VERSION ""

NS_ :

BS_:

BU_: VCU BMS ECUMASTER_GPS_IMU AMK_RL

BO_ 256 VCU_STATUS: 4 Vector__XXX
 SG_ VEHICLE_STATE : 0|2@1+ (1,0) [0|3] "Enum" Vector__XXX
 SG_ TORQUE_PLAUSIBLE : 2|1@1+ (1,0) [0|1] "Bool" Vector__XXX
 SG_ PEDALS_PLAUSIBLE : 3|1@1+ (1,0) [0|1] "Bool" Vector__XXX
 SG_ TORQUE_DERATING : 4|1@1+ (1,0) [0|0] "Bool" Vector__XXX
 SG_ VCU_EEPROM_STATE : 5|2@1+ (1,0) [0|0] "Enum" Vector__XXX
 SG_ CAN_PLAUSIBLE : 7|1@1+ (1,0) [0|1] "Bool" Vector__XXX
 SG_ APPS_1_PLAUSIBLE : 8|1@1+ (1,0) [0|1] "Bool" Vector__XXX
 SG_ APPS_1_CONFIG_PLAUSIBLE : 9|1@1+ (1,0) [0|1] "Bool" Vector__XXX
 SG_ APPS_2_PLAUSIBLE : 10|1@1+ (1,0) [0|1] "Bool" Vector__XXX
 SG_ APPS_2_CONFIG_PLAUSIBLE : 11|1@1+ (1,0) [0|1] "Bool" Vector__XXX
 SG_ BSE_F_PLAUSIBLE : 12|1@1+ (1,0) [0|1] "Bool" Vector__XXX
 SG_ BSE_F_CONFIG_PLAUSIBLE : 13|1@1+ (1,0) [0|1] "Bool" Vector__XXX
 SG_ BSE_R_PLAUSIBLE : 14|1@1+ (1,0) [0|1] "Bool" Vector__XXX
 SG_ BSE_R_CONFIG_PLAUSIBLE : 15|1@1+ (1,0) [0|1] "Bool" Vector__XXX
 SG_ AMK_RL_VALID : 16|1@1+ (1,0) [0|0] "Bool" Vector__XXX
 SG_ AMK_RR_VALID : 17|1@1+ (1,0) [0|0] "Bool" Vector__XXX
 SG_ AMK_FL_VALID : 18|1@1+ (1,0) [0|0] "Bool" Vector__XXX
 SG_ AMK_FR_VALID : 19|1@1+ (1,0) [0|0] "Bool" Vector__XXX
 SG_ GPS_VALID : 20|1@1+ (1,0) [0|0] "Bool" Vector__XXX
 SG_ GLV_BATTERY_VOLTAGE : 24|8@1+ (0.070588235294,0) [0|18] "V" Vector__XXX

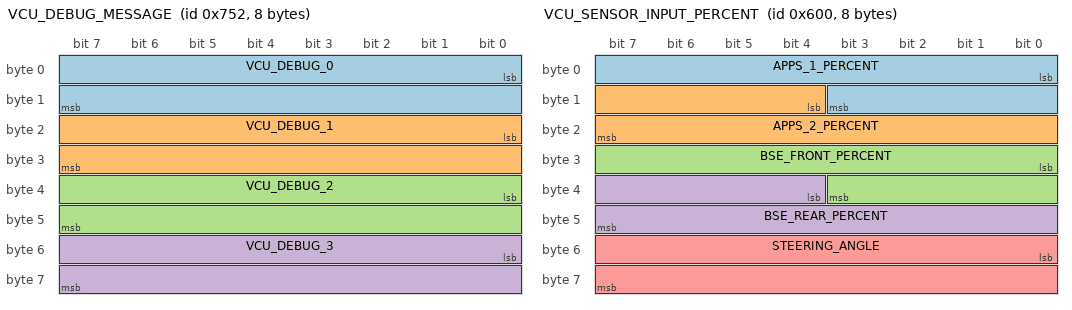
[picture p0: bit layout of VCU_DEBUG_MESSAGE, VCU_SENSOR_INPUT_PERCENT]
BO_ 1874 VCU_DEBUG_MESSAGE: 8 Vector__XXX
 SG_ VCU_DEBUG_0 : 0|16@1- (0.01,0) [0|0] "" Vector__XXX
 SG_ VCU_DEBUG_1 : 16|16@1- (0.01,0) [0|0] "" Vector__XXX
 SG_ VCU_DEBUG_2 : 32|16@1- (0.01,0) [0|0] "" Vector__XXX
 SG_ VCU_DEBUG_3 : 48|16@1- (0.01,0) [0|0] "" Vector__XXX

BO_ 1536 VCU_SENSOR_INPUT_PERCENT: 8 VCU
 SG_ APPS_1_PERCENT : 0|12@1+ (0.02442002442002442,0) [0|100] "%" Vector__XXX
 SG_ APPS_2_PERCENT : 12|12@1+ (0.02442002442002442,0) [0|100] "%" Vector__XXX
 SG_ BSE_FRONT_PERCENT : 24|12@1+ (0.02442002442002442,0) [0|100] "%" Vector__XXX
 SG_ BSE_REAR_PERCENT : 36|12@1+ (0.02442002442002442,0) [0|100] "%" Vector__XXX
 SG_ STEERING_ANGLE : 48|16@1- (0.005493247882810711,0) [-180|180] "Deg" Vector__XXX

BO_ 1284 AMK_RL_ERRORS_1: 8 AMK_RL
 SG_ RL_DIAGNOSTIC_NUMBER : 0|32@1+ (1,0) [0|0] "Word" Vector__XXX
 SG_ RL_ERROR_INFO_1 : 32|32@1+ (1,0) [0|0] "Word" Vector__XXX

BO_ 1288 AMK_RL_ERRORS_2: 8 AMK_RL
 SG_ RL_ERROR_INFO_2 : 0|32@1+ (1,0) [0|0] "Word" Vector__XXX
 SG_ RL_ERROR_INFO_3 : 32|32@1+ (1,0) [0|0] "Word" Vector__XXX

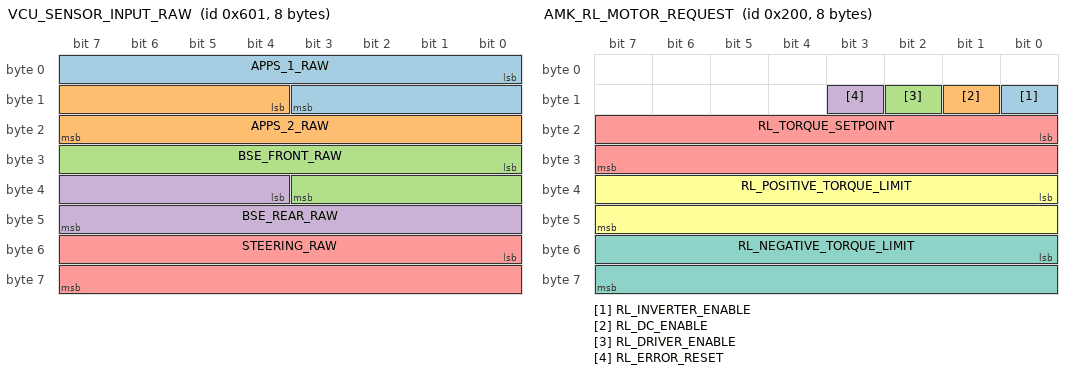
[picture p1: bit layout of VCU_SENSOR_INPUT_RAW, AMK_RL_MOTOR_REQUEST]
BO_ 1537 VCU_SENSOR_INPUT_RAW: 8 VCU
 SG_ APPS_1_RAW : 0|12@1+ (1,0) [0|4095] "Counts" Vector__XXX
 SG_ APPS_2_RAW : 12|12@1+ (1,0) [0|4095] "Counts" Vector__XXX
 SG_ BSE_FRONT_RAW : 24|12@1+ (1,0) [0|4095] "Counts" Vector__XXX
 SG_ BSE_REAR_RAW : 36|12@1+ (1,0) [0|4095] "Counts" Vector__XXX
 SG_ STEERING_RAW : 48|16@1+ (1,0) [0|4095] "Counts" Vector__XXX

BO_ 512 AMK_RL_MOTOR_REQUEST: 8 AMK_RL
 SG_ RL_INVERTER_ENABLE : 8|1@1+ (0,0) [0|0] "" Vector__XXX
 SG_ RL_DC_ENABLE : 9|1@1+ (0,0) [0|0] "" Vector__XXX
 SG_ RL_DRIVER_ENABLE : 10|1@1+ (0,0) [0|0] "" Vector__XXX
 SG_ RL_ERROR_RESET : 11|1@1+ (0,0) [0|0] "" Vector__XXX
 SG_ RL_TORQUE_SETPOINT : 16|16@1- (0.0098,0) [-21|21] "Nm" Vector__XXX
 SG_ RL_POSITIVE_TORQUE_LIMIT : 32|16@1- (0.0098,0) [0|21] "Nm" Vector__XXX
 SG_ RL_NEGATIVE_TORQUE_LIMIT : 48|16@1- (0.0098,0) [0|21] "Nm" Vector__XXX

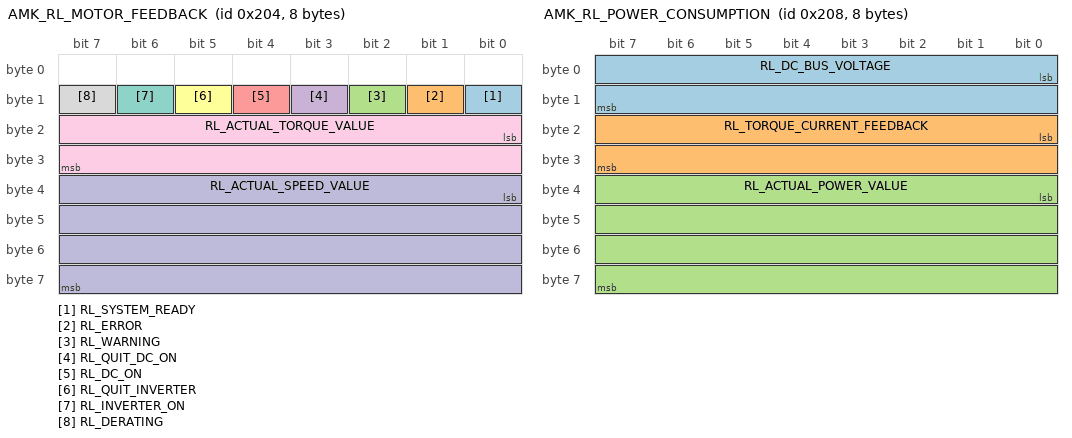
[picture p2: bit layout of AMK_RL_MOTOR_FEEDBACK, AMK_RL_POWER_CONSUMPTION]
BO_ 516 AMK_RL_MOTOR_FEEDBACK: 8 AMK_RL
 SG_ RL_SYSTEM_READY : 8|1@1+ (1,0) [0|0] "Bool" Vector__XXX
 SG_ RL_ERROR : 9|1@1+ (1,0) [0|0] "Bool" Vector__XXX
 SG_ RL_WARNING : 10|1@1+ (1,0) [0|0] "Bool" Vector__XXX
 SG_ RL_QUIT_DC_ON : 11|1@1+ (1,0) [0|0] "Bool" Vector__XXX
 SG_ RL_DC_ON : 12|1@1+ (1,0) [0|0] "Bool" Vector__XXX
 SG_ RL_QUIT_INVERTER : 13|1@1+ (1,0) [0|0] "Bool" Vector__XXX
 SG_ RL_INVERTER_ON : 14|1@1+ (1,0) [0|0] "Bool" Vector__XXX
 SG_ RL_DERATING : 15|1@1+ (1,0) [0|0] "Bool" Vector__XXX
 SG_ RL_ACTUAL_TORQUE_VALUE : 16|16@1- (0.0098,0) [0|0] "Nm" Vector__XXX
 SG_ RL_ACTUAL_SPEED_VALUE : 32|32@1- (0.00001,0) [0|0] "RPM" Vector__XXX

BO_ 520 AMK_RL_POWER_CONSUMPTION: 8 AMK_RL
 SG_ RL_DC_BUS_VOLTAGE : 0|16@1+ (1,0) [0|0] "V" Vector__XXX
 SG_ RL_TORQUE_CURRENT_FEEDBACK : 16|16@1- (1,0) [0|0] "A" Vector__XXX
 SG_ RL_ACTUAL_POWER_VALUE : 32|32@1+ (1,0) [0|0] "W" Vector__XXX

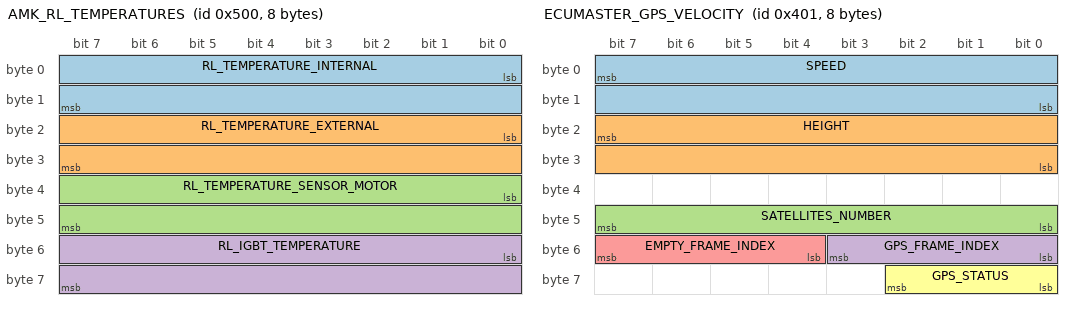
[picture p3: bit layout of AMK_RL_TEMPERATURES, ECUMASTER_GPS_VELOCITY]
BO_ 1280 AMK_RL_TEMPERATURES: 8 AMK_RL
 SG_ RL_TEMPERATURE_INTERNAL : 0|16@1- (0.1,0) [0|0] "C" Vector__XXX
 SG_ RL_TEMPERATURE_EXTERNAL : 16|16@1- (0.1,0) [0|0] "C" Vector__XXX
 SG_ RL_TEMPERATURE_SENSOR_MOTOR : 32|16@1+ (0.1,0) [0|0] "C" Vector__XXX
 SG_ RL_IGBT_TEMPERATURE : 48|16@1- (0.1,0) [0|0] "C" Vector__XXX

BO_ 1024 ECUMASTER_GPS_POSITION: 8 ECUMASTER_GPS_IMU
 SG_ LATITUDE : 7|32@0- (1e-7,0) [-90|90] "deg" Vector__XXX
 SG_ LONGITUDE : 39|32@0- (1e-7,0) [-180|180] "deg" Vector__XXX

BO_ 1025 ECUMASTER_GPS_VELOCITY: 8 ECUMASTER_GPS_IMU
 SG_ SPEED : 7|16@0- (0.036,0) [-1179|1179] "km/h" Vector__XXX
 SG_ HEIGHT : 23|16@0- (1,0) [-32768|32767] "m" Vector__XXX
 SG_ SATELLITES_NUMBER : 47|8@0+ (1,0) [0|72] "" Vector__XXX
 SG_ GPS_FRAME_INDEX : 51|4@0+ (1,0) [0|16] "" Vector__XXX
 SG_ EMPTY_FRAME_INDEX : 55|4@0+ (1,0) [0|16] "" Vector__XXX
 SG_ GPS_STATUS : 58|3@0+ (1,0) [1|5] "" Vector__XXX

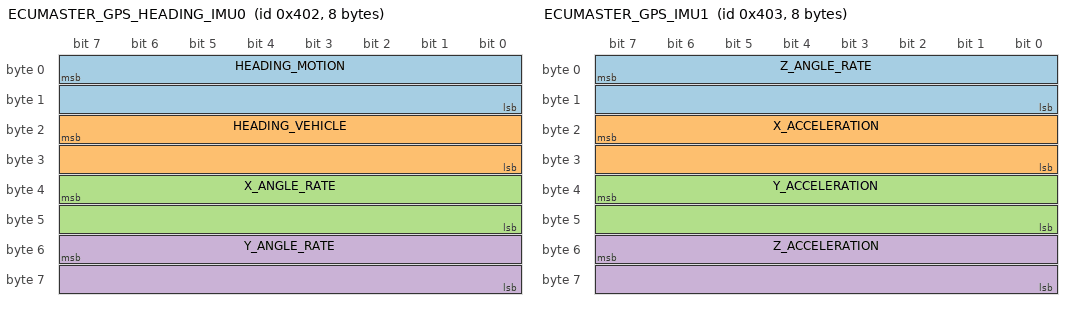
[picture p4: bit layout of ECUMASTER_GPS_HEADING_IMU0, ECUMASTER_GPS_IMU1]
BO_ 1026 ECUMASTER_GPS_HEADING_IMU0: 8 ECUMASTER_GPS_IMU
 SG_ HEADING_MOTION : 7|16@0+ (1,0) [0|360] "deg" Vector__XXX
 SG_ HEADING_VEHICLE : 23|16@0+ (1,0) [0|360] "deg" Vector__XXX
 SG_ X_ANGLE_RATE : 39|16@0- (0.01,0) [-250|250] "deg/s" Vector__XXX
 SG_ Y_ANGLE_RATE : 55|16@0- (0.01,0) [-250|250] "deg/s" Vector__XXX

BO_ 1027 ECUMASTER_GPS_IMU1: 8 ECUMASTER_GPS_IMU
 SG_ Z_ANGLE_RATE : 7|16@0- (0.01,0) [-250|250] "deg/s" Vector__XXX
 SG_ X_ACCELERATION : 23|16@0- (0.01,0) [-4|4] "g" Vector__XXX
 SG_ Y_ACCELERATION : 39|16@0- (0.01,0) [-4|4] "g" Vector__XXX
 SG_ Z_ACCELERATION : 55|16@0- (0.01,0) [-4|4] "g" Vector__XXX

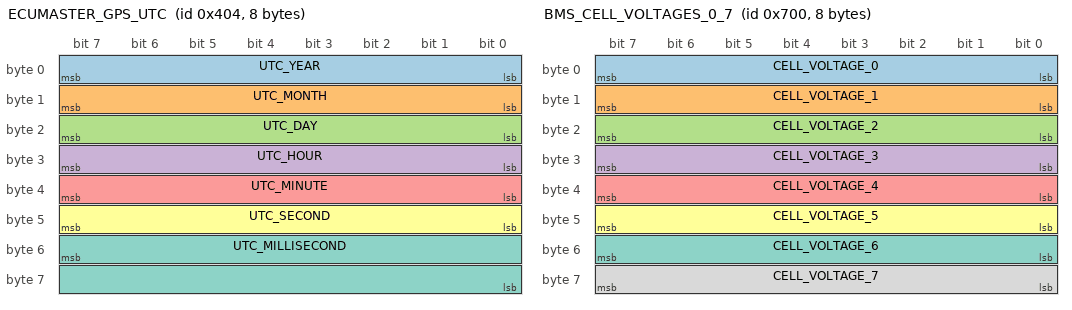
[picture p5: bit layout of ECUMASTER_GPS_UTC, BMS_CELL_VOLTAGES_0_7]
BO_ 1028 ECUMASTER_GPS_UTC: 8 ECUMASTER_GPS_IMU
 SG_ UTC_YEAR : 7|8@0+ (1,2000) [2000|2255] "years" Vector__XXX
 SG_ UTC_MONTH : 15|8@0+ (1,0) [1|12] "months" Vector__XXX
 SG_ UTC_DAY : 23|8@0+ (1,0) [1|31] "days" Vector__XXX
 SG_ UTC_HOUR : 31|8@0+ (1,0) [0|23] "hours" Vector__XXX
 SG_ UTC_MINUTE : 39|8@0+ (1,0) [0|59] "minutes" Vector__XXX
 SG_ UTC_SECOND : 47|8@0+ (1,0) [0|59] "s" Vector__XXX
 SG_ UTC_MILLISECOND : 55|16@0+ (0.0152587890625,0) [0|999.99] "ms" Vector__XXX

BO_ 1792 BMS_CELL_VOLTAGES_0_7: 8 BMS
 SG_ CELL_VOLTAGE_0 : 0|8@1+ (0.03125,0) [0|7.96875] "V" Vector__XXX
 SG_ CELL_VOLTAGE_1 : 8|8@1+ (0.03125,0) [0|7.96875] "V" Vector__XXX
 SG_ CELL_VOLTAGE_2 : 16|8@1+ (0.03125,0) [0|7.96875] "V" Vector__XXX
 SG_ CELL_VOLTAGE_3 : 24|8@1+ (0.03125,0) [0|7.96875] "V" Vector__XXX
 SG_ CELL_VOLTAGE_4 : 32|8@1+ (0.03125,0) [0|7.96875] "V" Vector__XXX
 SG_ CELL_VOLTAGE_5 : 40|8@1+ (0.03125,0) [0|7.96875] "V" Vector__XXX
 SG_ CELL_VOLTAGE_6 : 48|8@1+ (0.03125,0) [0|7.96875] "V" Vector__XXX
 SG_ CELL_VOLTAGE_7 : 56|8@1+ (0.03125,0) [0|7.96875] "V" Vector__XXX

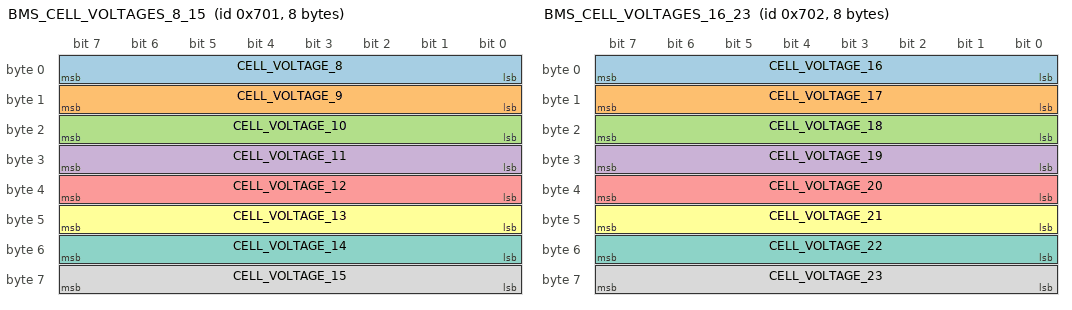
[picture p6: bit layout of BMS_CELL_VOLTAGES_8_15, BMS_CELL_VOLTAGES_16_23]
BO_ 1793 BMS_CELL_VOLTAGES_8_15: 8 BMS
 SG_ CELL_VOLTAGE_8 : 0|8@1+ (0.03125,0) [0|7.96875] "V" Vector__XXX
 SG_ CELL_VOLTAGE_9 : 8|8@1+ (0.03125,0) [0|7.96875] "V" Vector__XXX
 SG_ CELL_VOLTAGE_10 : 16|8@1+ (0.03125,0) [0|7.96875] "V" Vector__XXX
 SG_ CELL_VOLTAGE_11 : 24|8@1+ (0.03125,0) [0|7.96875] "V" Vector__XXX
 SG_ CELL_VOLTAGE_12 : 32|8@1+ (0.03125,0) [0|7.96875] "V" Vector__XXX
 SG_ CELL_VOLTAGE_13 : 40|8@1+ (0.03125,0) [0|7.96875] "V" Vector__XXX
 SG_ CELL_VOLTAGE_14 : 48|8@1+ (0.03125,0) [0|7.96875] "V" Vector__XXX
 SG_ CELL_VOLTAGE_15 : 56|8@1+ (0.03125,0) [0|7.96875] "V" Vector__XXX

BO_ 1794 BMS_CELL_VOLTAGES_16_23: 8 BMS
 SG_ CELL_VOLTAGE_16 : 0|8@1+ (0.03125,0) [0|7.96875] "V" Vector__XXX
 SG_ CELL_VOLTAGE_17 : 8|8@1+ (0.03125,0) [0|7.96875] "V" Vector__XXX
 SG_ CELL_VOLTAGE_18 : 16|8@1+ (0.03125,0) [0|7.96875] "V" Vector__XXX
 SG_ CELL_VOLTAGE_19 : 24|8@1+ (0.03125,0) [0|7.96875] "V" Vector__XXX
 SG_ CELL_VOLTAGE_20 : 32|8@1+ (0.03125,0) [0|7.96875] "V" Vector__XXX
 SG_ CELL_VOLTAGE_21 : 40|8@1+ (0.03125,0) [0|7.96875] "V" Vector__XXX
 SG_ CELL_VOLTAGE_22 : 48|8@1+ (0.03125,0) [0|7.96875] "V" Vector__XXX
 SG_ CELL_VOLTAGE_23 : 56|8@1+ (0.03125,0) [0|7.96875] "V" Vector__XXX

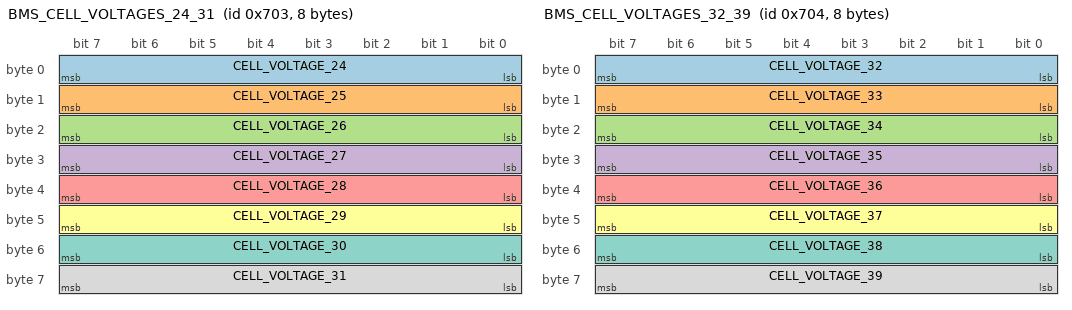
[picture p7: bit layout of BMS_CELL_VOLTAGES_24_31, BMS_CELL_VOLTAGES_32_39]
BO_ 1795 BMS_CELL_VOLTAGES_24_31: 8 BMS
 SG_ CELL_VOLTAGE_24 : 0|8@1+ (0.03125,0) [0|7.96875] "V" Vector__XXX
 SG_ CELL_VOLTAGE_25 : 8|8@1+ (0.03125,0) [0|7.96875] "V" Vector__XXX
 SG_ CELL_VOLTAGE_26 : 16|8@1+ (0.03125,0) [0|7.96875] "V" Vector__XXX
 SG_ CELL_VOLTAGE_27 : 24|8@1+ (0.03125,0) [0|7.96875] "V" Vector__XXX
 SG_ CELL_VOLTAGE_28 : 32|8@1+ (0.03125,0) [0|7.96875] "V" Vector__XXX
 SG_ CELL_VOLTAGE_29 : 40|8@1+ (0.03125,0) [0|7.96875] "V" Vector__XXX
 SG_ CELL_VOLTAGE_30 : 48|8@1+ (0.03125,0) [0|7.96875] "V" Vector__XXX
 SG_ CELL_VOLTAGE_31 : 56|8@1+ (0.03125,0) [0|7.96875] "V" Vector__XXX

BO_ 1796 BMS_CELL_VOLTAGES_32_39: 8 BMS
 SG_ CELL_VOLTAGE_32 : 0|8@1+ (0.03125,0) [0|7.96875] "V" Vector__XXX
 SG_ CELL_VOLTAGE_33 : 8|8@1+ (0.03125,0) [0|7.96875] "V" Vector__XXX
 SG_ CELL_VOLTAGE_34 : 16|8@1+ (0.03125,0) [0|7.96875] "V" Vector__XXX
 SG_ CELL_VOLTAGE_35 : 24|8@1+ (0.03125,0) [0|7.96875] "V" Vector__XXX
 SG_ CELL_VOLTAGE_36 : 32|8@1+ (0.03125,0) [0|7.96875] "V" Vector__XXX
 SG_ CELL_VOLTAGE_37 : 40|8@1+ (0.03125,0) [0|7.96875] "V" Vector__XXX
 SG_ CELL_VOLTAGE_38 : 48|8@1+ (0.03125,0) [0|7.96875] "V" Vector__XXX
 SG_ CELL_VOLTAGE_39 : 56|8@1+ (0.03125,0) [0|7.96875] "V" Vector__XXX

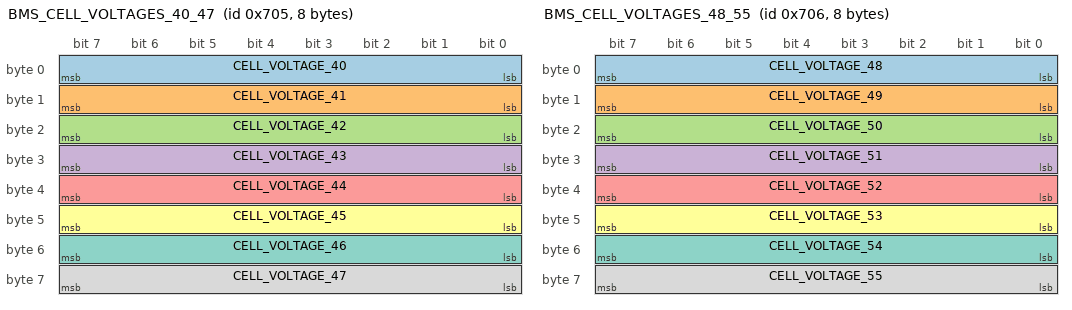
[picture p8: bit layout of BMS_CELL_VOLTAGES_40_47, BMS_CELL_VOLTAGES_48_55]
BO_ 1797 BMS_CELL_VOLTAGES_40_47: 8 BMS
 SG_ CELL_VOLTAGE_40 : 0|8@1+ (0.03125,0) [0|7.96875] "V" Vector__XXX
 SG_ CELL_VOLTAGE_41 : 8|8@1+ (0.03125,0) [0|7.96875] "V" Vector__XXX
 SG_ CELL_VOLTAGE_42 : 16|8@1+ (0.03125,0) [0|7.96875] "V" Vector__XXX
 SG_ CELL_VOLTAGE_43 : 24|8@1+ (0.03125,0) [0|7.96875] "V" Vector__XXX
 SG_ CELL_VOLTAGE_44 : 32|8@1+ (0.03125,0) [0|7.96875] "V" Vector__XXX
 SG_ CELL_VOLTAGE_45 : 40|8@1+ (0.03125,0) [0|7.96875] "V" Vector__XXX
 SG_ CELL_VOLTAGE_46 : 48|8@1+ (0.03125,0) [0|7.96875] "V" Vector__XXX
 SG_ CELL_VOLTAGE_47 : 56|8@1+ (0.03125,0) [0|7.96875] "V" Vector__XXX

BO_ 1798 BMS_CELL_VOLTAGES_48_55: 8 BMS
 SG_ CELL_VOLTAGE_48 : 0|8@1+ (0.03125,0) [0|7.96875] "V" Vector__XXX
 SG_ CELL_VOLTAGE_49 : 8|8@1+ (0.03125,0) [0|7.96875] "V" Vector__XXX
 SG_ CELL_VOLTAGE_50 : 16|8@1+ (0.03125,0) [0|7.96875] "V" Vector__XXX
 SG_ CELL_VOLTAGE_51 : 24|8@1+ (0.03125,0) [0|7.96875] "V" Vector__XXX
 SG_ CELL_VOLTAGE_52 : 32|8@1+ (0.03125,0) [0|7.96875] "V" Vector__XXX
 SG_ CELL_VOLTAGE_53 : 40|8@1+ (0.03125,0) [0|7.96875] "V" Vector__XXX
 SG_ CELL_VOLTAGE_54 : 48|8@1+ (0.03125,0) [0|7.96875] "V" Vector__XXX
 SG_ CELL_VOLTAGE_55 : 56|8@1+ (0.03125,0) [0|7.96875] "V" Vector__XXX

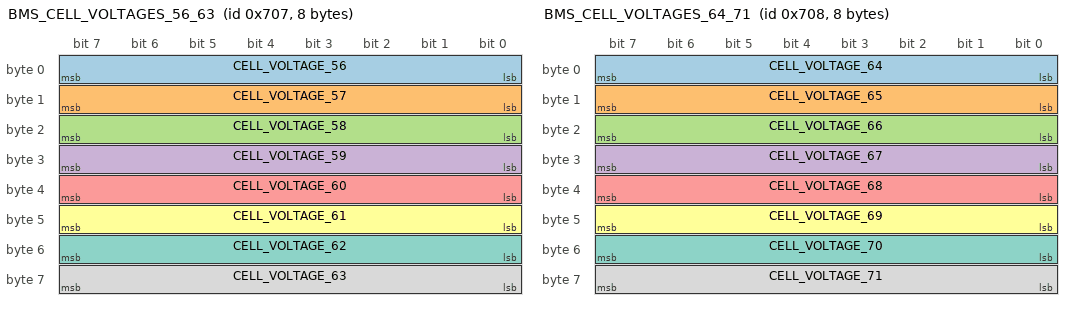
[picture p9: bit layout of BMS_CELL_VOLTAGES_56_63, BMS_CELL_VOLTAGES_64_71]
BO_ 1799 BMS_CELL_VOLTAGES_56_63: 8 BMS
 SG_ CELL_VOLTAGE_56 : 0|8@1+ (0.03125,0) [0|7.96875] "V" Vector__XXX
 SG_ CELL_VOLTAGE_57 : 8|8@1+ (0.03125,0) [0|7.96875] "V" Vector__XXX
 SG_ CELL_VOLTAGE_58 : 16|8@1+ (0.03125,0) [0|7.96875] "V" Vector__XXX
 SG_ CELL_VOLTAGE_59 : 24|8@1+ (0.03125,0) [0|7.96875] "V" Vector__XXX
 SG_ CELL_VOLTAGE_60 : 32|8@1+ (0.03125,0) [0|7.96875] "V" Vector__XXX
 SG_ CELL_VOLTAGE_61 : 40|8@1+ (0.03125,0) [0|7.96875] "V" Vector__XXX
 SG_ CELL_VOLTAGE_62 : 48|8@1+ (0.03125,0) [0|7.96875] "V" Vector__XXX
 SG_ CELL_VOLTAGE_63 : 56|8@1+ (0.03125,0) [0|7.96875] "V" Vector__XXX

BO_ 1800 BMS_CELL_VOLTAGES_64_71: 8 BMS
 SG_ CELL_VOLTAGE_64 : 0|8@1+ (0.03125,0) [0|7.96875] "V" Vector__XXX
 SG_ CELL_VOLTAGE_65 : 8|8@1+ (0.03125,0) [0|7.96875] "V" Vector__XXX
 SG_ CELL_VOLTAGE_66 : 16|8@1+ (0.03125,0) [0|7.96875] "V" Vector__XXX
 SG_ CELL_VOLTAGE_67 : 24|8@1+ (0.03125,0) [0|7.96875] "V" Vector__XXX
 SG_ CELL_VOLTAGE_68 : 32|8@1+ (0.03125,0) [0|7.96875] "V" Vector__XXX
 SG_ CELL_VOLTAGE_69 : 40|8@1+ (0.03125,0) [0|7.96875] "V" Vector__XXX
 SG_ CELL_VOLTAGE_70 : 48|8@1+ (0.03125,0) [0|7.96875] "V" Vector__XXX
 SG_ CELL_VOLTAGE_71 : 56|8@1+ (0.03125,0) [0|7.96875] "V" Vector__XXX

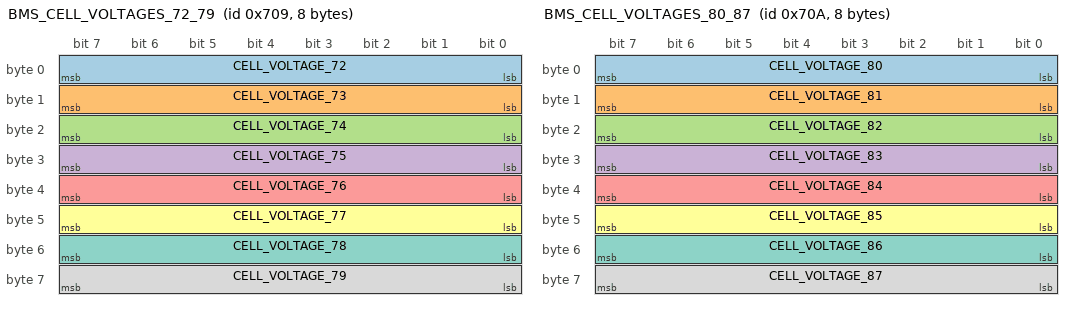
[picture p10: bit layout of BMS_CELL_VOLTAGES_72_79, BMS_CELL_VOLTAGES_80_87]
BO_ 1801 BMS_CELL_VOLTAGES_72_79: 8 BMS
 SG_ CELL_VOLTAGE_72 : 0|8@1+ (0.03125,0) [0|7.96875] "V" Vector__XXX
 SG_ CELL_VOLTAGE_73 : 8|8@1+ (0.03125,0) [0|7.96875] "V" Vector__XXX
 SG_ CELL_VOLTAGE_74 : 16|8@1+ (0.03125,0) [0|7.96875] "V" Vector__XXX
 SG_ CELL_VOLTAGE_75 : 24|8@1+ (0.03125,0) [0|7.96875] "V" Vector__XXX
 SG_ CELL_VOLTAGE_76 : 32|8@1+ (0.03125,0) [0|7.96875] "V" Vector__XXX
 SG_ CELL_VOLTAGE_77 : 40|8@1+ (0.03125,0) [0|7.96875] "V" Vector__XXX
 SG_ CELL_VOLTAGE_78 : 48|8@1+ (0.03125,0) [0|7.96875] "V" Vector__XXX
 SG_ CELL_VOLTAGE_79 : 56|8@1+ (0.03125,0) [0|7.96875] "V" Vector__XXX

BO_ 1802 BMS_CELL_VOLTAGES_80_87: 8 BMS
 SG_ CELL_VOLTAGE_80 : 0|8@1+ (0.03125,0) [0|7.96875] "V" Vector__XXX
 SG_ CELL_VOLTAGE_81 : 8|8@1+ (0.03125,0) [0|7.96875] "V" Vector__XXX
 SG_ CELL_VOLTAGE_82 : 16|8@1+ (0.03125,0) [0|7.96875] "V" Vector__XXX
 SG_ CELL_VOLTAGE_83 : 24|8@1+ (0.03125,0) [0|7.96875] "V" Vector__XXX
 SG_ CELL_VOLTAGE_84 : 32|8@1+ (0.03125,0) [0|7.96875] "V" Vector__XXX
 SG_ CELL_VOLTAGE_85 : 40|8@1+ (0.03125,0) [0|7.96875] "V" Vector__XXX
 SG_ CELL_VOLTAGE_86 : 48|8@1+ (0.03125,0) [0|7.96875] "V" Vector__XXX
 SG_ CELL_VOLTAGE_87 : 56|8@1+ (0.03125,0) [0|7.96875] "V" Vector__XXX

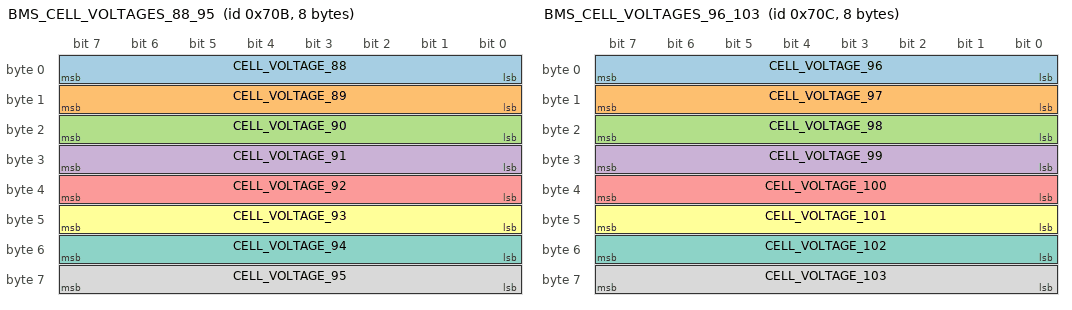
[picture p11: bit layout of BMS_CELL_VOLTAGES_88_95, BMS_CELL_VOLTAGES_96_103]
BO_ 1803 BMS_CELL_VOLTAGES_88_95: 8 BMS
 SG_ CELL_VOLTAGE_88 : 0|8@1+ (0.03125,0) [0|7.96875] "V" Vector__XXX
 SG_ CELL_VOLTAGE_89 : 8|8@1+ (0.03125,0) [0|7.96875] "V" Vector__XXX
 SG_ CELL_VOLTAGE_90 : 16|8@1+ (0.03125,0) [0|7.96875] "V" Vector__XXX
 SG_ CELL_VOLTAGE_91 : 24|8@1+ (0.03125,0) [0|7.96875] "V" Vector__XXX
 SG_ CELL_VOLTAGE_92 : 32|8@1+ (0.03125,0) [0|7.96875] "V" Vector__XXX
 SG_ CELL_VOLTAGE_93 : 40|8@1+ (0.03125,0) [0|7.96875] "V" Vector__XXX
 SG_ CELL_VOLTAGE_94 : 48|8@1+ (0.03125,0) [0|7.96875] "V" Vector__XXX
 SG_ CELL_VOLTAGE_95 : 56|8@1+ (0.03125,0) [0|7.96875] "V" Vector__XXX

BO_ 1804 BMS_CELL_VOLTAGES_96_103: 8 BMS
 SG_ CELL_VOLTAGE_96 : 0|8@1+ (0.03125,0) [0|7.96875] "V" Vector__XXX
 SG_ CELL_VOLTAGE_97 : 8|8@1+ (0.03125,0) [0|7.96875] "V" Vector__XXX
 SG_ CELL_VOLTAGE_98 : 16|8@1+ (0.03125,0) [0|7.96875] "V" Vector__XXX
 SG_ CELL_VOLTAGE_99 : 24|8@1+ (0.03125,0) [0|7.96875] "V" Vector__XXX
 SG_ CELL_VOLTAGE_100 : 32|8@1+ (0.03125,0) [0|7.96875] "V" Vector__XXX
 SG_ CELL_VOLTAGE_101 : 40|8@1+ (0.03125,0) [0|7.96875] "V" Vector__XXX
 SG_ CELL_VOLTAGE_102 : 48|8@1+ (0.03125,0) [0|7.96875] "V" Vector__XXX
 SG_ CELL_VOLTAGE_103 : 56|8@1+ (0.03125,0) [0|7.96875] "V" Vector__XXX

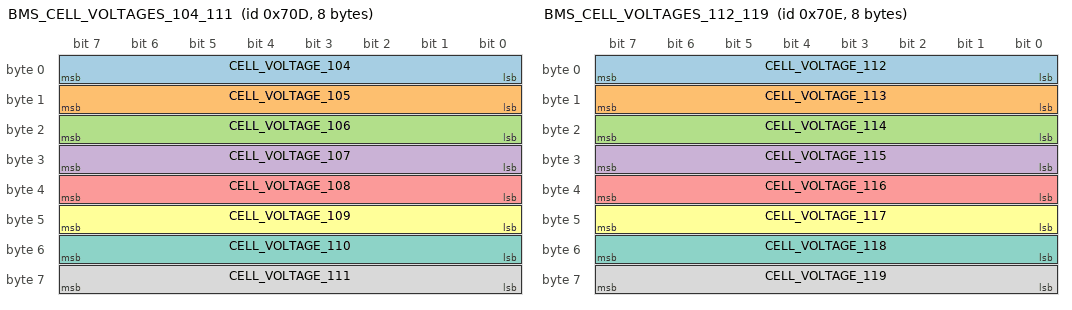
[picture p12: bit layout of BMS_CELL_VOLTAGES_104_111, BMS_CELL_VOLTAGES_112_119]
BO_ 1805 BMS_CELL_VOLTAGES_104_111: 8 BMS
 SG_ CELL_VOLTAGE_104 : 0|8@1+ (0.03125,0) [0|7.96875] "V" Vector__XXX
 SG_ CELL_VOLTAGE_105 : 8|8@1+ (0.03125,0) [0|7.96875] "V" Vector__XXX
 SG_ CELL_VOLTAGE_106 : 16|8@1+ (0.03125,0) [0|7.96875] "V" Vector__XXX
 SG_ CELL_VOLTAGE_107 : 24|8@1+ (0.03125,0) [0|7.96875] "V" Vector__XXX
 SG_ CELL_VOLTAGE_108 : 32|8@1+ (0.03125,0) [0|7.96875] "V" Vector__XXX
 SG_ CELL_VOLTAGE_109 : 40|8@1+ (0.03125,0) [0|7.96875] "V" Vector__XXX
 SG_ CELL_VOLTAGE_110 : 48|8@1+ (0.03125,0) [0|7.96875] "V" Vector__XXX
 SG_ CELL_VOLTAGE_111 : 56|8@1+ (0.03125,0) [0|7.96875] "V" Vector__XXX

BO_ 1806 BMS_CELL_VOLTAGES_112_119: 8 BMS
 SG_ CELL_VOLTAGE_112 : 0|8@1+ (0.03125,0) [0|7.96875] "V" Vector__XXX
 SG_ CELL_VOLTAGE_113 : 8|8@1+ (0.03125,0) [0|7.96875] "V" Vector__XXX
 SG_ CELL_VOLTAGE_114 : 16|8@1+ (0.03125,0) [0|7.96875] "V" Vector__XXX
 SG_ CELL_VOLTAGE_115 : 24|8@1+ (0.03125,0) [0|7.96875] "V" Vector__XXX
 SG_ CELL_VOLTAGE_116 : 32|8@1+ (0.03125,0) [0|7.96875] "V" Vector__XXX
 SG_ CELL_VOLTAGE_117 : 40|8@1+ (0.03125,0) [0|7.96875] "V" Vector__XXX
 SG_ CELL_VOLTAGE_118 : 48|8@1+ (0.03125,0) [0|7.96875] "V" Vector__XXX
 SG_ CELL_VOLTAGE_119 : 56|8@1+ (0.03125,0) [0|7.96875] "V" Vector__XXX

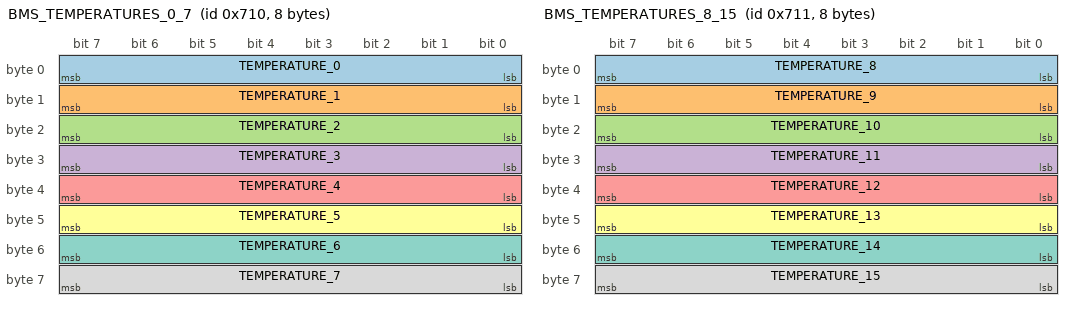
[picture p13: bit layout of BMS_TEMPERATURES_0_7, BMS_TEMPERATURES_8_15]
BO_ 1808 BMS_TEMPERATURES_0_7: 8 BMS
 SG_ TEMPERATURE_0 : 0|8@1+ (0.5,-28) [-28|99.5] "C" Vector__XXX
 SG_ TEMPERATURE_1 : 8|8@1+ (0.5,-28) [-28|99.5] "C" Vector__XXX
 SG_ TEMPERATURE_2 : 16|8@1+ (0.5,-28) [-28|99.5] "C" Vector__XXX
 SG_ TEMPERATURE_3 : 24|8@1+ (0.5,-28) [-28|99.5] "C" Vector__XXX
 SG_ TEMPERATURE_4 : 32|8@1+ (0.5,-28) [-28|99.5] "C" Vector__XXX
 SG_ TEMPERATURE_5 : 40|8@1+ (0.5,-28) [-28|99.5] "C" Vector__XXX
 SG_ TEMPERATURE_6 : 48|8@1+ (0.5,-28) [-28|99.5] "C" Vector__XXX
 SG_ TEMPERATURE_7 : 56|8@1+ (0.5,-28) [-28|99.5] "C" Vector__XXX

BO_ 1809 BMS_TEMPERATURES_8_15: 8 BMS
 SG_ TEMPERATURE_8 : 0|8@1+ (0.5,-28) [-28|99.5] "C" Vector__XXX
 SG_ TEMPERATURE_9 : 8|8@1+ (0.5,-28) [-28|99.5] "C" Vector__XXX
 SG_ TEMPERATURE_10 : 16|8@1+ (0.5,-28) [-28|99.5] "C" Vector__XXX
 SG_ TEMPERATURE_11 : 24|8@1+ (0.5,-28) [-28|99.5] "C" Vector__XXX
 SG_ TEMPERATURE_12 : 32|8@1+ (0.5,-28) [-28|99.5] "C" Vector__XXX
 SG_ TEMPERATURE_13 : 40|8@1+ (0.5,-28) [-28|99.5] "C" Vector__XXX
 SG_ TEMPERATURE_14 : 48|8@1+ (0.5,-28) [-28|99.5] "C" Vector__XXX
 SG_ TEMPERATURE_15 : 56|8@1+ (0.5,-28) [-28|99.5] "C" Vector__XXX

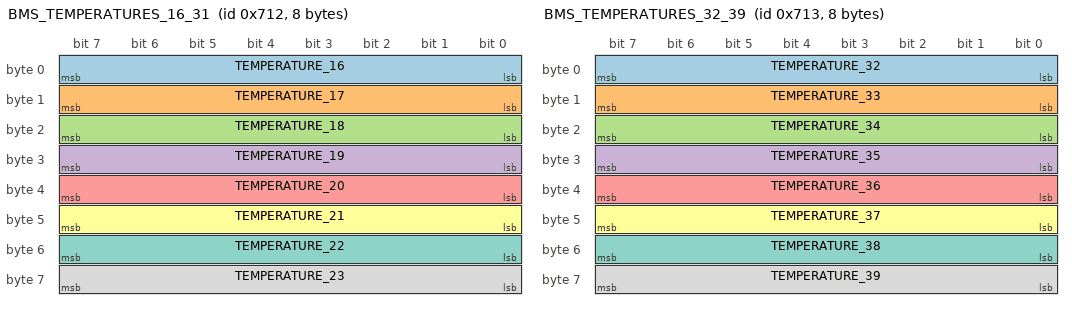
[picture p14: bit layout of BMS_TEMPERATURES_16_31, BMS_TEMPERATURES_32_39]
BO_ 1810 BMS_TEMPERATURES_16_31: 8 BMS
 SG_ TEMPERATURE_16 : 0|8@1+ (0.5,-28) [-28|99.5] "C" Vector__XXX
 SG_ TEMPERATURE_17 : 8|8@1+ (0.5,-28) [-28|99.5] "C" Vector__XXX
 SG_ TEMPERATURE_18 : 16|8@1+ (0.5,-28) [-28|99.5] "C" Vector__XXX
 SG_ TEMPERATURE_19 : 24|8@1+ (0.5,-28) [-28|99.5] "C" Vector__XXX
 SG_ TEMPERATURE_20 : 32|8@1+ (0.5,-28) [-28|99.5] "C" Vector__XXX
 SG_ TEMPERATURE_21 : 40|8@1+ (0.5,-28) [-28|99.5] "C" Vector__XXX
 SG_ TEMPERATURE_22 : 48|8@1+ (0.5,-28) [-28|99.5] "C" Vector__XXX
 SG_ TEMPERATURE_23 : 56|8@1+ (0.5,-28) [-28|99.5] "C" Vector__XXX

BO_ 1811 BMS_TEMPERATURES_32_39: 8 BMS
 SG_ TEMPERATURE_32 : 0|8@1+ (0.5,-28) [-28|99.5] "C" Vector__XXX
 SG_ TEMPERATURE_33 : 8|8@1+ (0.5,-28) [-28|99.5] "C" Vector__XXX
 SG_ TEMPERATURE_34 : 16|8@1+ (0.5,-28) [-28|99.5] "C" Vector__XXX
 SG_ TEMPERATURE_35 : 24|8@1+ (0.5,-28) [-28|99.5] "C" Vector__XXX
 SG_ TEMPERATURE_36 : 32|8@1+ (0.5,-28) [-28|99.5] "C" Vector__XXX
 SG_ TEMPERATURE_37 : 40|8@1+ (0.5,-28) [-28|99.5] "C" Vector__XXX
 SG_ TEMPERATURE_38 : 48|8@1+ (0.5,-28) [-28|99.5] "C" Vector__XXX
 SG_ TEMPERATURE_39 : 56|8@1+ (0.5,-28) [-28|99.5] "C" Vector__XXX

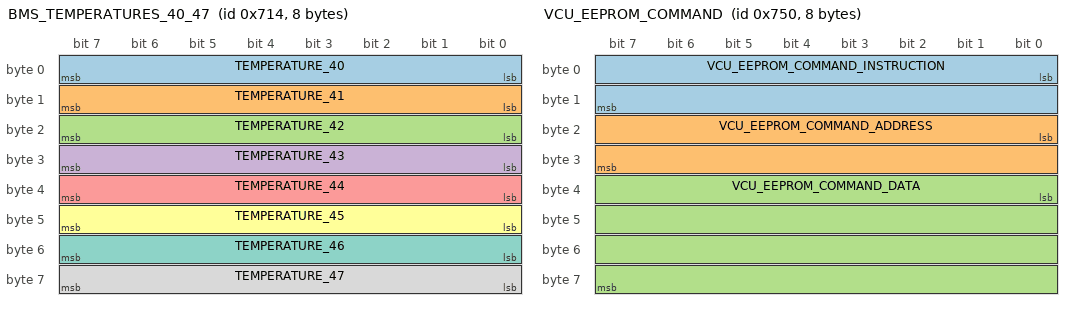
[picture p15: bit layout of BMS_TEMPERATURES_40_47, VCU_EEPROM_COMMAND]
BO_ 1812 BMS_TEMPERATURES_40_47: 8 BMS
 SG_ TEMPERATURE_40 : 0|8@1+ (0.5,-28) [-28|99.5] "C" Vector__XXX
 SG_ TEMPERATURE_41 : 8|8@1+ (0.5,-28) [-28|99.5] "C" Vector__XXX
 SG_ TEMPERATURE_42 : 16|8@1+ (0.5,-28) [-28|99.5] "C" Vector__XXX
 SG_ TEMPERATURE_43 : 24|8@1+ (0.5,-28) [-28|99.5] "C" Vector__XXX
 SG_ TEMPERATURE_44 : 32|8@1+ (0.5,-28) [-28|99.5] "C" Vector__XXX
 SG_ TEMPERATURE_45 : 40|8@1+ (0.5,-28) [-28|99.5] "C" Vector__XXX
 SG_ TEMPERATURE_46 : 48|8@1+ (0.5,-28) [-28|99.5] "C" Vector__XXX
 SG_ TEMPERATURE_47 : 56|8@1+ (0.5,-28) [-28|99.5] "C" Vector__XXX

BO_ 1813 BMS_TEMPERATURES_48_49: 8 BMS
 SG_ TEMPERATURE_48 : 0|8@1+ (0.5,-28) [-28|99.5] "C" Vector__XXX
 SG_ TEMPERATURE_49 : 8|8@1+ (0.5,-28) [-28|99.5] "C" Vector__XXX

BO_ 1872 VCU_EEPROM_COMMAND: 8 Vector__XXX
 SG_ VCU_EEPROM_COMMAND_INSTRUCTION : 0|16@1+ (0,0) [0|0] "" Vector__XXX
 SG_ VCU_EEPROM_COMMAND_ADDRESS : 16|16@1+ (0,0) [0|0] "" Vector__XXX
 SG_ VCU_EEPROM_COMMAND_DATA : 32|32@1+ (0,0) [0|0] "" Vector__XXX

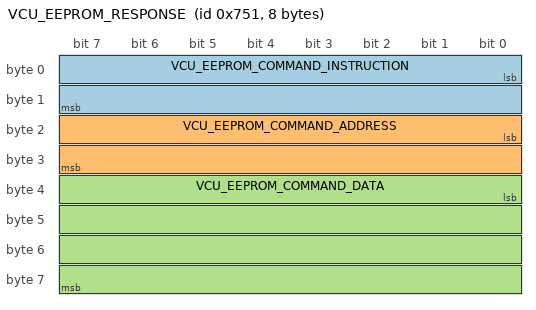
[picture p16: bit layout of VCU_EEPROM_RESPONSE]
BO_ 1873 VCU_EEPROM_RESPONSE: 8 Vector__XXX
 SG_ VCU_EEPROM_COMMAND_INSTRUCTION : 0|16@1+ (0,0) [0|0] "" Vector__XXX
 SG_ VCU_EEPROM_COMMAND_ADDRESS : 16|16@1+ (0,0) [0|0] "" Vector__XXX
 SG_ VCU_EEPROM_COMMAND_DATA : 32|32@1+ (0,0) [0|0] "" Vector__XXX

BO_ 233 MOTEC_RESERVED_0: 0 Vector__XXX
 SG_  : 0|0@1+ (0,0) [0|0] "" Vector__XXX

BO_ 864 MOTEC_RESERVED_1: 0 Vector__XXX
 SG_  : 0|0@1+ (0,0) [0|0] "" Vector__XXX

BO_ 865 MOTEC_RESERVED_2: 0 Vector__XXX
 SG_  : 0|0@1+ (0,0) [0|0] "" Vector__XXX

BO_ 866 MOTEC_RESERVED_3: 0 Vector__XXX
 SG_  : 0|0@1+ (0,0) [0|0] "" Vector__XXX

BO_ 879 MOTEC_RESERVED_4: 0 Vector__XXX
 SG_  : 0|0@1+ (0,0) [0|0] "" Vector__XXX

BO_ 889 MOTEC_RESERVED_5: 0 Vector__XXX
 SG_  : 0|0@1+ (0,0) [0|0] "" Vector__XXX

BO_ 890 MOTEC_RESERVED_6: 0 Vector__XXX
 SG_  : 0|0@1+ (0,0) [0|0] "" Vector__XXX

BO_ 894 MOTEC_RESERVED_7: 0 Vector__XXX

CM_ SG_ 1280 RL_TEMPERATURE_EXTERNAL "TODO(Barach): No documented scale factor";
CM_ SG_ 1280 RL_TEMPERATURE_SENSOR_MOTOR "TODO(Barach): No documented scale factor";

BA_DEF_  "BusType" STRING ;
BA_DEF_DEF_  "BusType" "CAN";
